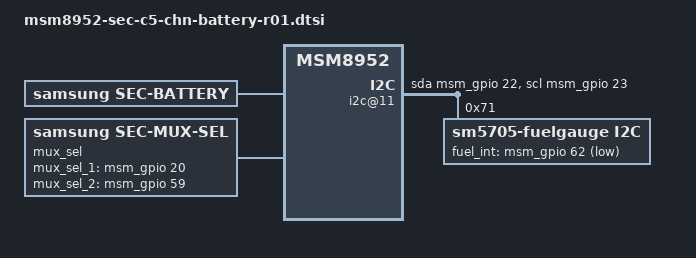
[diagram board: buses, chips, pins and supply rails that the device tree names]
/* Copyright (c) 2014, The Linux Foundation. All rights reserved.
 *
 * This program is free software; you can redistribute it and/or modify
 * it under the terms of the GNU General Public License version 2 and
 * only version 2 as published by the Free Software Foundation.
 *
 * This program is distributed in the hope that it will be useful,
 * but WITHOUT ANY WARRANTY; without even the implied warranty of
 * MERCHANTABILITY or FITNESS FOR A PARTICULAR PURPOSE.  See the
 * GNU General Public License for more details.
 */

/ {
	i2c@11 {
		cell-index = <11>;
		compatible = "i2c-gpio";
		gpios = <&msm_gpio 22 0 // sda
			&msm_gpio 23 0	// scl
			>;
		i2c-gpio,delay-us = <2>;
		#address-cells = <1>;
		#size-cells = <0>;

		sm5705-fuelgauge@71{
			compatible = "sm5705-fuelgauge,i2c";
			reg = <0x71>;
			interrupt-parent = <&msm_gpio>;
			pinctrl-names = "default";
			pinctrl-0 = <&fg_i2c_active &fuel_int_active>;
			fuelgauge,irqf = "IRQF_TRIGGER_FALLING + IRQF_ONESHOT + IRQF_NO_SUSPEND";
			fuelgauge,fuel_int = <&msm_gpio 62 0x1>;
			fuelgauge,fuel_alert_soc = <1>;
			fuelgauge,capacity_max = <1000>;
			fuelgauge,capacity_max_margin = <70>;
			fuelgauge,capacity_min = <0>;
			fuelgauge,capacity_calculation_type = <0x1F>;
		};
	};

	battery {
		status = "okay";
		compatible = "samsung,sec-battery";
		battery,vendor = "SDI SDI";
		battery,charger_name = "sm5705-charger";
		battery,fuelgauge_name = "sm5705-fuelgauge";
		battery,technology = <2>; /* POWER_SUPPLY_TECHNOLOGY_LION */

		battery,chip_vendor = "QCOM";
		battery,temp_adc_type = <1>; /* SEC_BATTERY_ADC_TYPE_AP */

		battery,polling_time = <10 30 30 30 3600>;

		battery,temp_table_adc = <26000 26467 27134 27550 27965 28531 29175 29600 29760 29919 30792 32737 34869 37004 38534 38861 39764 40457 41041 41518>;

		battery,temp_table_data = <900 800 700 650 600 550 500 470 460 450 400 300 200 100 20 0 (-50) (-100) (-150) (-200)>;

		battery,chg_temp_table_adc = <26000 26467 27134 27550 27965 28531 29175 29600 29760 29919 30792 32737 34869 37004 38534 38861 39764 40457 41041 41518>;

		battery,chg_temp_table_data = <900 800 700 650 600 550 500 470 460 450 400 300 200 100 20 0 (-50) (-100) (-150) (-200)>;
		battery,adc_check_count = <5>;

		battery,input_current_limit = <1800 500 500 1800 500 900 1000 500 500 1000 820 1800 1800 500 1300 300 700 1300 1500 300 80 900 1500 1000 1000 1650 1650 1650 1400 1000 1000>;
		battery,fast_charging_current = <2100 0 500 2100 500 1200 1000 500 0 1200 1000 2100 2100 0 1300 300 700 1300 1500 300 80 1200 1500 1000 1000 2700 1000 2700 1400 0 1000>;
		battery,full_check_current_1st = <290 0 290 290 290 290 290 290 0 290 290 290 290 0 290 290 290 290 290 290 290 290 0 290 290 290 290 290 290 0 290>;
		battery,full_check_current_2nd = <90 0 90 90 90 90 90 90 0 90 90 90 90 0 90 90 90 90 90 90 90 90 0 90 90 90 90 90 90 0 90>;

		battery,cable_check_type = <4>; /* SEC_BATTERY_CABLE_CHECK_PSY */
		battery,cable_source_type = <3>; /* SEC_BATTERY_CABLE_SOURCE_EXTERNAL */

		battery,chg_thermal_source = <1>;
		battery,chg_temp_check;
		battery,chg_high_temp_1st = <465>;
		battery,chg_high_temp_2nd = <465>;
		battery,chg_high_temp = <510>;
		battery,chg_high_temp_recovery = <455>;
		battery,chg_charging_limit_current = <1500>;
		battery,chg_skip_check_capacity = <10>;
		battery,chg_skip_check_time = <900>;

		battery,event_waiting_time = <600>;
		battery,polling_type = <1>; /* SEC_BATTERY_MONITOR_ALARM */
		battery,monitor_initial_count = <3>;

		battery,battery_check_type = <0>; /* SEC_BATTERY_CHECK_NONE */
		battery,check_count = <0>;
		battery,check_adc_max = <1440>;
		battery,check_adc_min = <0>;

		battery,ovp_uvlo_check_type = <3>; /* SEC_BATTERY_OVP_UVLO_CHGPOLLING */

		battery,thermal_source = <2>; /* SEC_BATTERY_THERMAL_SOURCE_ADC */

		battery,temp_check_type = <2>; /* SEC_BATTERY_TEMP_CHECK_TEMP */
		battery,temp_check_count = <1>;
		battery,temp_highlimit_threshold_event = <800>;
		battery,temp_highlimit_recovery_event = <750>;
		battery,temp_high_threshold_event = <550>;
		battery,temp_high_recovery_event = <500>;
		battery,temp_low_threshold_event = <(-50)>;
		battery,temp_low_recovery_event = <0>;
		battery,temp_highlimit_threshold_normal = <800>;
		battery,temp_highlimit_recovery_normal = <750>;
		battery,temp_high_threshold_normal = <550>;
		battery,temp_high_recovery_normal = <500>;
		battery,temp_low_threshold_normal = <(-50)>;
		battery,temp_low_recovery_normal = <0>;
		battery,temp_highlimit_threshold_lpm = <800>;
		battery,temp_highlimit_recovery_lpm = <750>;
		battery,temp_high_threshold_lpm = <550>;
		battery,temp_high_recovery_lpm = <500>;
		battery,temp_low_threshold_lpm = <(-50)>;
		battery,temp_low_recovery_lpm = <0>;
		battery,full_check_type = <2>; /* SEC_BATTERY_FULLCHARGED_FG_CURRENT */
		battery,full_check_type_2nd = <2>; /* SEC_BATTERY_FULLCHARGED_FG_CURRENT */
		battery,full_check_count = <1>;
		battery,chg_gpio_full_check = <0>;
		battery,chg_polarity_full_check = <1>;

		/* SEC_BATTERY_FULL_CONDITION_SOC |
		   SEC_BATTERY_FULL_CONDITION_NOTIMEFULL |
		   SEC_BATTERY_FULL_CONDITION_VCELL */
		battery,full_condition_type = <13>;
		battery,full_condition_soc = <93>;
		battery,full_condition_vcell = <4300>;

		battery,recharge_check_count = <1>;
		battery,recharge_condition_type = <4>; /* SEC_BATTERY_RECHARGE_CONDITION_VCELL */
		battery,recharge_condition_soc = <98>;
		battery,recharge_condition_vcell = <4340>;

		//battery,self_discharging_en;
		battery,self_discharging_type = <2>;	/* SEC_BAT_SELF_DISCHARGING_BY_CHG */
		battery,force_discharging_limit = <600>;
		battery,force_discharging_recov = <550>;
		battery,self_discharging_voltage_limit = <4250>;
		battery,discharging_adc_max = <29864>;
		battery,discharging_adc_min = <25768>;
		battery,discharging_ntc_limit = <2750>;

		battery,charging_total_time = <21600>;
		battery,recharging_total_time = <5400>;
		battery,charging_reset_time = <0>;

		//battery,swelling_chg_current = <1500>;
		battery,swelling_high_chg_current = <1900>;
		battery,swelling_low_chg_current = <1400>;
		battery,swelling_full_check_current_2nd = <145>;

		battery,swelling_high_temp_block = <500>;
		battery,swelling_high_temp_recov = <450>;
		battery,swelling_low_temp_block = <50>;
		battery,swelling_low_temp_recov = <100>;
		battery,swelling_chg_current = <1500>;
		battery,swelling_drop_float_voltage = <4200>;
		battery,swelling_high_rechg_voltage = <4150>;
		battery,swelling_low_rechg_voltage = <4050>;
		battery,swelling_block_time = <600>;

		battery,self_discharging_temp_block = <600>;
		battery,self_discharging_volt_block = <4250>;
		battery,self_discharging_temp_recov = <550>;
		battery,self_discharging_temp_pollingtime = <400>;

		battery,chg_float_voltage = <4390>;
	
		qcom,sec-battery-vadc = <&pm8950_vadc>;

		charger {
			status = "disable";
			/* Charger */
			battery,charger_name = "sm5705-charger";
			battery,chgen_gpio = <&msm_gpio 21 0x0>;

			battery,chg_float_voltage = <4390>;

			battery,chg_polarity_en = <0>;
			battery,chg_gpio_status = <0>;
			battery,chg_polarity_status = <0>;

			battery,siop_input_limit_current = <1200>;
			battery,siop_charging_limit_current = <1000>;
			battery,siop_hv_input_limit_current = <700>;
			battery,siop_hv_charging_limit_current = <1000>;

			battery,siop_wireless_input_limit_current = <700>;
			battery,siop_wireless_charging_limit_current = <600>;
			battery,siop_hv_wireless_input_limit_current = <500>;
			battery,siop_hv_wireless_charging_limit_current = <1000>;
			battery,siop_call_cv_current = <500>;
			battery,siop_call_cc_current = <500>;

		battery,input_current_limit = <1800 500 500 1800 500 900 1000 500 500 1000 820 1800 1800 500 1300 300 700 1300 1500 300 80 900 1500 1000 1000 1650 1650 1650 1400 1000 1000>;
		battery,fast_charging_current = <2100 0 500 2100 500 1200 1000 500 0 1200 1000 2100 2100 0 1300 300 700 1300 1500 300 80 1200 1500 1000 1000 2700 1000 2700 1400 0 1000>;
		battery,full_check_current_1st = <290 0 290 290 290 290 290 290 0 290 290 290 290 0 290 290 290 290 290 290 290 290 0 290 290 290 290 290 290 0 290>;
		battery,full_check_current_2nd = <90 0 90 90 90 90 90 90 0 90 90 90 90 0 90 90 90 90 90 90 90 90 0 90 90 90 90 90 90 0 90>;

		};
	};
	mux_sel {
		compatible = "samsung,sec-mux-sel";
		mux_sel,mux_sel_1_en = <1>;
		mux_sel,mux_sel_1 = <&msm_gpio 20 0x0>;
		mux_sel,mux_sel_1_type = <24>; /* CHG_THM_MUX_SEL | AP_THM_MUX_SEL */
		mux_sel,mux_sel_1_mpp = <4>; /* SEC_MPP4_MUX_SEL */
		mux_sel,mux_sel_1_low = <4>; /* SEC_MUX_SEL_AP_THM */
		mux_sel,mux_sel_1_high = <3>; /* SEC_MUX_SEL_CHG_THM */

		mux_sel,mux_sel_2_en = <1>;
		mux_sel,mux_sel_2 = <&msm_gpio 59 0x0>;
		mux_sel,mux_sel_2_type = <5>; /* EAR_ADC_MUX_SEL | BATT_THM_MUX_SEL */
		mux_sel,mux_sel_2_mpp = <2>; /* SEC_MPP2_MUX_SEL */
		mux_sel,mux_sel_2_low = <2>; /* SEC_MUX_SEL_BATT_THM */
		mux_sel,mux_sel_2_high = <0>; /* SEC_MUX_SEL_EAR_ADC */
	};

	battery_params {
		battery,id = <0>; /* -1 means auto, detected by F/G */
		battery0,battery_type = <4400>; /* 4200 4350 4400 */
		battery0,battery_table0 = <0x1400 0x1B33 0x1D1A 0x1D79 0x1D8E 0x1DED 0x1E39 0x1E74 0x1EE5 0x1F33 0x1FA8 0x1FFB 0x20FB 0x2257 0x22D2 0x2399>;
		battery0,battery_table1 = <0x0 0x2F 0xE4 0x14F 0x28E 0x41E 0x638 0x84C 0xAE6 0xBF0 0xCFA 0xE04 0x10A3 0x13C2 0x14CC 0x14DC>;
		battery0,temp_std = <25>;
		battery0,temp_cal = <1 6 1 11 (-1) 1 6 1 9 1>; /* en_h, p_de, p_fa, n_de, n_fa, en_l, p_de, p_fa, n_de, n_fa, */
		battery0,ext_temp_cal = <0 2 1 2 1 1 2 3 2 3>; /* en_h, p_de, p_fa, n_de, n_fa, en_l, p_de, p_fa, n_de, n_fa, */
		battery0,temp_volcal = <1 15 1>; /* en, temp, cal */
		battery0,temp_offset = <1 11 1 1 8 (-1)>; /* en_high level offset en_low level offset */
		battery0,cycle_cfg = <7 1 3>; /*high_limit low_limit cntl*/
		battery0,rce_value = <0x04E1 0x03E6 0x01D7>;
		battery0,dtcd_value = <0x1>;
		battery0,rs_value = <0x0051 0x147 0x47a 0x3800 0x00a4>; /*rs p_mix_factor n_mix_factor max min*/
		battery0,vit_period = <0x3506>;
		battery0,mix_value = <0x0503 0x0004>; /*mix_rate init_blank*/
		battery0,misc = <0x0060>;
		battery0,topoff_soc = <0 3 300>; /*enable soc current*/
		battery0,curr_offset = <1 0x0000>; /*en_auto offset*/
		battery0,full_offset = <20 4>; /*margin extra_offset*/
		battery0,volt_cal = <0x8000>;
		battery0,p_curr_cal = <0x0084>;
		battery0,n_curr_cal = <0x0078>;
		battery0,curr_lcal = <0 0x8888 0x8888 0x8888>;
		battery0,tem_poff = <3350 50 3250 50>;
		battery0,v_offset_cancel = <1 0 100 10>; /* en_p, en_n, level, mohm */
		battery0,v_alarm = <3100>;
	};

};
